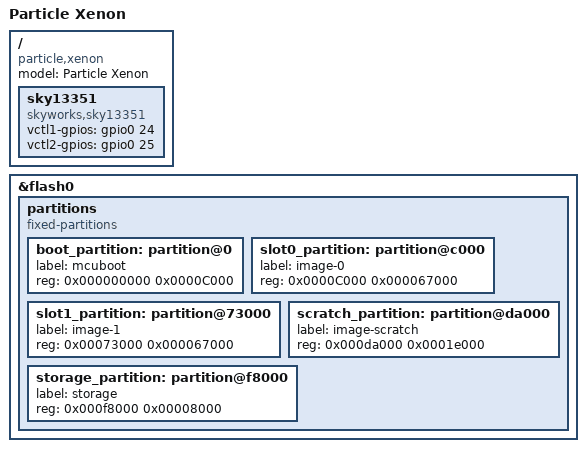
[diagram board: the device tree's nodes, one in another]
/*
 * Copyright (c) 2018 Endre Karlson
 * Copyright (c) 2018 Peter Bigot Consulting, LLC
 *
 * SPDX-License-Identifier: Apache-2.0
 */

/dts-v1/;
#include <nordic/nrf52840_qiaa.dtsi>
#include "mesh_feather.dtsi"

/ {
	model = "Particle Xenon";
	compatible = "particle,xenon", "particle,feather",
		"nordic,nrf52840-qiaa", "nordic,nrf52840";

	sky13351 {
		compatible = "skyworks,sky13351";
		vctl1-gpios = <&gpio0 24 0>;
		vctl2-gpios = <&gpio0 25 0>;
	};
};
&flash0 {
        /*
         * For more information, see:
         * http://docs.zephyrproject.org/latest/guides/dts/index.html#flash-partitions
         */
        partitions {
                compatible = "fixed-partitions";
                #address-cells = <1>;
                #size-cells = <1>;

                boot_partition: partition@0 {
                        label = "mcuboot";
                        reg = <0x000000000 0x0000C000>;
                };
                slot0_partition: partition@c000 {
                        label = "image-0";
                        reg = <0x0000C000 0x000067000>;
                };
                slot1_partition: partition@73000 {
                        label = "image-1";
                        reg = <0x00073000 0x000067000>;
                };
                scratch_partition: partition@da000 {
                        label = "image-scratch";
                        reg = <0x000da000 0x0001e000>;
                };

                /*
                 * The flash starting at 0x000f8000 and ending at
                 * 0x000fffff is reserved for use by the application.
                 */

                /* Storage partition will be used by FCB/NFFS/NVS if enabled. */
                storage_partition: partition@f8000 {
                        label = "storage";
                        reg = <0x000f8000 0x00008000>;
                };
        };
};
